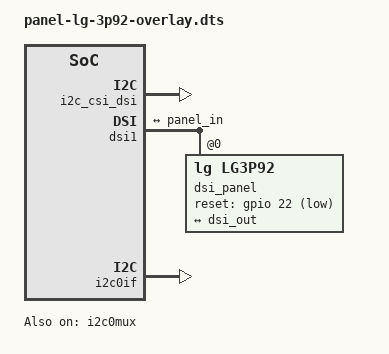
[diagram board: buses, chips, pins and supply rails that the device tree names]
/dts-v1/;
/plugin/;

// #include <dt-bindings/gpio/gpio.h>
// #include <dt-bindings/interrupt-controller/irq.h>

/ {
	// compatible = "brcm,bcm2835";

	i2c_frag: fragment@0 {
		target = <&i2c_csi_dsi>;
		__overlay__ {
			#address-cells = <1>;
			#size-cells = <0>;
			status = "okay";
		};
	};

	dsi_frag: fragment@1 {
		target = <&dsi1>;
		__overlay__  {
			#address-cells = <1>;
			#size-cells = <0>;
			status = "okay";

			port {
				dsi_out: endpoint {
					remote-endpoint = <&panel_in>;
				};
			};
			
			dsi_panel: dsi_panel@0 {
				reg = <0>;
				compatible = "lg,lg3p92";
				reset-gpios = <&gpio 22 1>;

				port {
					panel_in: endpoint {
						remote-endpoint = <&dsi_out>;
					};
				};
			};
		};
	};

	fragment@2 {
		target = <&i2c0if>;
		__overlay__ {
			status = "okay";
		};
	};

	fragment@3 {
		target = <&i2c0mux>;
		__overlay__ {
			status = "okay";
		};
	};
};
